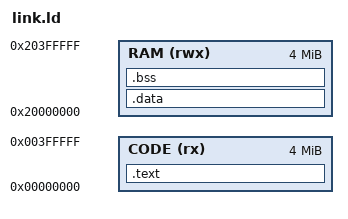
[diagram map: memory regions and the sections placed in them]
/* QEMU mps2-an386 (Cortex-M4): 4M SSRAM at 0 for code, 4M at 0x20000000 */
MEMORY
{
    CODE (rx)  : ORIGIN = 0x00000000, LENGTH = 4M
    RAM  (rwx) : ORIGIN = 0x20000000, LENGTH = 4M
}

ENTRY(reset)

SECTIONS
{
    .text : {
        KEEP(*(.vectors))
        *(.text*)
        *(.rodata*)
        . = ALIGN(4);
        _etext = .;
    } > CODE

    .data : AT(_etext) {
        _sdata = .;
        *(.data*)
        . = ALIGN(4);
        _edata = .;
    } > RAM

    .bss (NOLOAD) : {
        _sbss = .;
        *(.bss*)
        *(COMMON)
        . = ALIGN(4);
        _ebss = .;
        end = .;
    } > RAM

    _estack = ORIGIN(RAM) + LENGTH(RAM);
}
